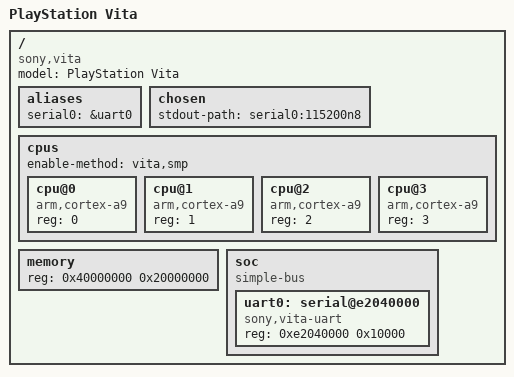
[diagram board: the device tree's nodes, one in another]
// SPDX-License-Identifier: GPL-2.0+
/*
 * Base Device Tree Source for the PlayStation Vita
 */

/dts-v1/;

#include <dt-bindings/gpio/gpio.h>
#include <dt-bindings/interrupt-controller/arm-gic.h>

/ {
	model = "PlayStation Vita";
	compatible = "sony,vita";

	#address-cells = <1>;
	#size-cells = <1>;

	aliases {
		serial0 = &uart0;
	};

	chosen {
		#address-cells = <1>;
		#size-cells = <1>;
		ranges;
		stdout-path = "serial0:115200n8";
	};

	cpus {
		#address-cells = <1>;
		#size-cells = <0>;
		enable-method = "vita,smp";

		cpu@0 {
			device_type = "cpu";
			compatible = "arm,cortex-a9";
			reg = <0>;
		};

		cpu@1 {
			device_type = "cpu";
			compatible = "arm,cortex-a9";
			reg = <1>;
		};

		cpu@2 {
			device_type = "cpu";
			compatible = "arm,cortex-a9";
			reg = <2>;
		};

		cpu@3 {
			device_type = "cpu";
			compatible = "arm,cortex-a9";
			reg = <3>;
		};
	};

	memory {
		device_type = "memory";
		reg = <0x40000000 0x20000000>;
	};

	soc {
		#address-cells = <1>;
		#size-cells = <1>;
		compatible = "simple-bus";
		ranges;

		uart0: serial@e2040000 {
			compatible = "sony,vita-uart";
			reg = <0xe2040000 0x10000>;
		};
	};
};

&uart0 {
	status = "okay";
};
